# rCSL_sc_001 register map
Vendor: Texas Instruments
Peripheral module from a debugger description file (folder c674x).
Registers are 32-bit, read-only, reset 0x0 unless marked. A register's access mark holds for its fields unless they carry their own. Offsets are as the file gives them; lines under a group give offsets from that group; [hi:lo] are bit positions; {n}, {i} and the like mark numbered series; 'fields as' and 'values as' point back to an identical list; <NAME> marks a mode.

## SEC_CTL — The Security Controller (sec_ctl) provides the management of the security state within the Security Architecture
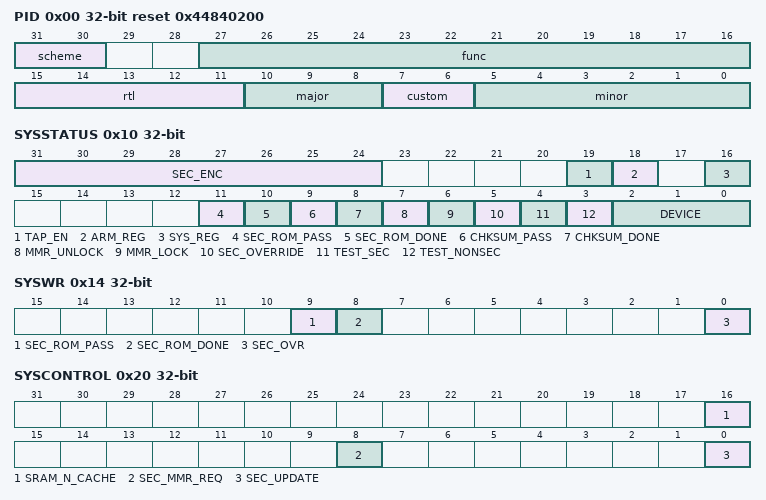
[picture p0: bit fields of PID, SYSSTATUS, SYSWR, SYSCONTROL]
0x00 PID reset 0x44840200 (reset mask 0xFFFF07FF) — Peripheral ID Register
  [31:30] scheme, [27:16] func, [15:11] rtl, [10:8] major, [7:6] custom, [5:0] minor
0x10 SYSSTATUS (reset mask 0xFFFFFFF8) — System Ststus Register
  [31:24] SEC_ENC
  [19] TAP_EN
    0=RNW (Register not yet written); 1=RW (Register written; no further writes allowed)
  [18] ARM_REG
    values as TAP_EN
  [16] SYS_REG
    values as TAP_EN
  [11] SEC_ROM_PASS
  [10] SEC_ROM_DONE
  [9] CHKSUM_PASS
    0=CSND (Checksum calculations not done); 1=CSD (Checksum calculations done)
  [8] CHKSUM_DONE
  [7] MMR_UNLOCK
  [6] MMR_LOCK
  [5] SEC_OVERRIDE
  [4] TEST_SEC
  [3] TEST_NONSEC
  [2:0] DEVICE
    0=TEST; 1=BAD
0x14 SYSWR access per field — System Write Once Register
  [9] SEC_ROM_PASS rw
    0=FAIL (Secure ROM failed checks); 1=PASS (Secure ROM passed checks)
  [8] SEC_ROM_DONE rw
    0=NOT_DONE (Secure ROM has not been validated); 1=DONE (All checks have been performed on Secure ROM)
  [0] SEC_OVR rw
    0=NO_SEC_OVR (No security override); 1=SEC_OVR (Security override granted)
0x1C ARMWR access per field — ARM Write Once Register
  [0] CP15S_DISABLE rw
    0=PASS (cp15 registers can be configured); 1=FAIL (c15 registers cannot be configured)
0x20 SYSCONTROL access per field — System Control Register
  [16] SRAM_N_CACHE rw — GEM SRAM not Cache
  [8] SEC_MMR_REQ rw — Test as Secure MMR Request
  [0] SEC_UPDATE rw — Security Controller Update
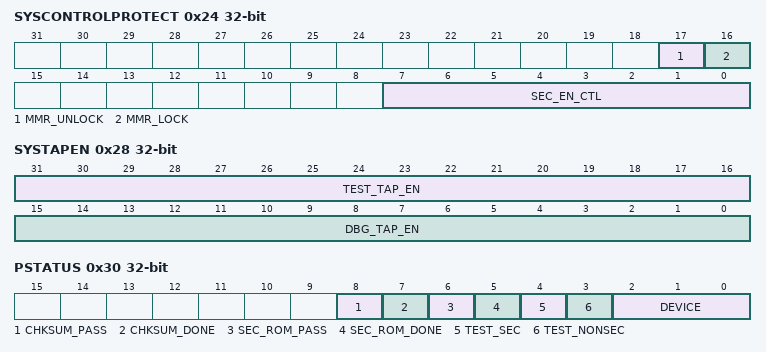
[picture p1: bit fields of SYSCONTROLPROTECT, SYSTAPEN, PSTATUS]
0x24 SYSCONTROLPROTECT access per field — System Control Protected Register
  [17] MMR_UNLOCK rw
    0=MMR_LOCK; 1=MMR_UNLOCK
  [16] MMR_LOCK rw
    0=MMR_UNLOCK; 1=MMR_LOCK
  [7:0] SEC_EN_CTL rw — Secure Enable Control
0x28 SYSTAPEN rw — System Tap Enable Register
  [31:16] TEST_TAP_EN — Bit =1 indicates Test TAP can be selected by ICEPick Bit =0 indicates Test TAP cannot be selected
  [15:0] DBG_TAP_EN — Bit =1 indicates Debug TAP can be selected by ICEPick Bit =0 indicates Debug TAP cannot be selected
0x2C SECRESERVED — Security Reserved Register
  [23:0] SEC_RSVD — Security Reserved Field
0x30 PSTATUS access not given (reset mask 0xFFFFFFF8) — P1500 Status Register
  [8] CHKSUM_PASS ro — Secure Checksum Pass
  [7] CHKSUM_DONE ro — Secure Checksum Done
  [6] SEC_ROM_PASS ro — Secure ROM Pass
  [5] SEC_ROM_DONE ro — Secure ROM Done
  [4] TEST_SEC ro — Test as Secure Request
  [3] TEST_NONSEC ro — Test as Non Secure Request
  [2:0] DEVICE — Device Type
0x34 PREADDEBUGDAT — P1500 Read Debug Data Register
  [31:0] DEBUG
0x38 PWRITEDEBUGDAT wo — P1500 Write Debug Data Register
  [31:0] DEBUG
